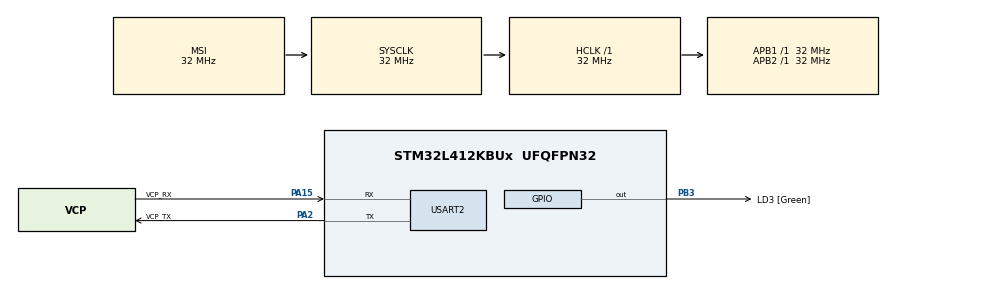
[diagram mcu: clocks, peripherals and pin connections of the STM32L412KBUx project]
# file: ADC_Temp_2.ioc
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ADC1.Channel-2\#ChannelRegularConversion=ADC_CHANNEL_TEMPSENSOR
ADC1.Channel-3\#ChannelRegularConversion=ADC_CHANNEL_VREFINT
ADC1.ClockPrescaler=ADC_CLOCK_ASYNC_DIV4
ADC1.ContinuousConvMode=DISABLE
ADC1.DataAlign=ADC_DATAALIGN_RIGHT
ADC1.ExternalTrigConv=ADC_SOFTWARE_START
ADC1.NbrOfConversion=2
ADC1.NbrOfConversionFlag=1
ADC1.OffsetNumber-2\#ChannelRegularConversion=ADC_OFFSET_NONE
ADC1.OffsetNumber-3\#ChannelRegularConversion=ADC_OFFSET_NONE
ADC1.Rank-2\#ChannelRegularConversion=1
ADC1.Rank-3\#ChannelRegularConversion=2
ADC1.SamplingTime-2\#ChannelRegularConversion=ADC_SAMPLETIME_92CYCLES_5
ADC1.SamplingTime-3\#ChannelRegularConversion=ADC_SAMPLETIME_2CYCLES_5
ADC1.master=1
Dma.ADC1.0.Direction=DMA_PERIPH_TO_MEMORY
Dma.ADC1.0.Instance=DMA1_Channel1
Dma.ADC1.0.MemDataAlignment=DMA_MDATAALIGN_HALFWORD
Dma.ADC1.0.MemInc=DMA_MINC_ENABLE
Dma.ADC1.0.Mode=DMA_NORMAL
Dma.ADC1.0.PeriphDataAlignment=DMA_PDATAALIGN_HALFWORD
Dma.ADC1.0.PeriphInc=DMA_PINC_DISABLE
Dma.ADC1.0.Priority=DMA_PRIORITY_LOW
Dma.Request0=ADC1
Mcu.Family=STM32L4
Mcu.Name=STM32L412KBUx
Mcu.Package=UFQFPN32
NVIC.DMA1_Channel1_IRQn=true\:0\:0\:false\:false\:true\:false\:true\:true
NVIC.PriorityGroup=NVIC_PRIORITYGROUP_4
NVIC.TIM2_IRQn=true\:0\:0\:false\:false\:true\:true\:true\:true
PA0-CK_IN.Mode=HSE-External-Clock-Source-for-LittleOrca
PA0-CK_IN.Signal=RCC_CK_IN
PA13\ (JTMS/SWDIO).GPIO_Label=SWDIO
PA13\ (JTMS/SWDIO).Mode=Serial_Wire
PA13\ (JTMS/SWDIO).Signal=SYS_JTMS-SWDIO
PA14\ (JTCK/SWCLK).GPIO_Label=SWCLK
PA14\ (JTCK/SWCLK).Mode=Serial_Wire
PA14\ (JTCK/SWCLK).Signal=SYS_JTCK-SWCLK
PA15\ (JTDI).GPIO_Label=VCP_RX
PA15\ (JTDI).Mode=Asynchronous
PA15\ (JTDI).Signal=USART2_RX
PA2.GPIO_Label=VCP_TX
PA2.Mode=Asynchronous
PA2.Signal=USART2_TX
PB3\ (JTDO/TRACESWO).GPIO_Label=LD3 [Green]
PB3\ (JTDO/TRACESWO).Signal=GPIO_Output
PC14-OSC32_IN\ (PC14).Mode=LSE-External-Oscillator
PC14-OSC32_IN\ (PC14).Signal=RCC_OSC32_IN
PC15-OSC32_OUT\ (PC15).Mode=LSE-External-Oscillator
PC15-OSC32_OUT\ (PC15).Signal=RCC_OSC32_OUT
ProjectManager.HeapSize=0x200
ProjectManager.StackSize=0x400
ProjectManager.TargetToolchain=STM32CubeIDE
RCC.ADCFreq_Value=32000000
RCC.AHBFreq_Value=32000000
RCC.APB1Freq_Value=32000000
RCC.APB1TimFreq_Value=32000000
RCC.APB2Freq_Value=32000000
RCC.APB2TimFreq_Value=32000000
RCC.CortexFreq_Value=32000000
RCC.FLatency=FLASH_LATENCY_1
RCC.HCLKFreq_Value=32000000
RCC.HSE_VALUE=8000000
RCC.HSI48_VALUE=48000000
RCC.HSICalibrationValue=64
RCC.HSI_VALUE=16000000
RCC.MSIClockRange=RCC_MSIRANGE_10
RCC.MSI_VALUE=32000000
RCC.PLLN=18
RCC.SYSCLKFreq_VALUE=32000000
RCC.USBFreq_Value=32000000
RCC.VCOOutputFreq_Value=576000000
TIM2.Period=10000-1
TIM2.Prescaler=6400-1
TIM2.TIM_MasterOutputTrigger=TIM_TRGO_UPDATE
USART2.VirtualMode-Asynchronous=VM_ASYNC
VP_ADC1_TempSens_Input.Mode=IN-TempSens
VP_ADC1_Vref_Input.Mode=IN-Vrefint
VP_TIM2_VS_ClockSourceINT.Mode=Internal
board=NUCLEO-L412KB

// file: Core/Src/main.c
/* USER CODE BEGIN Header */
/**
  ******************************************************************************
  * @file           : main.c
  * @brief          : Main program body
  ******************************************************************************
  * @attention
  *
  * Copyright (c) 2024 STMicroelectronics.
  * All rights reserved.
  *
  * This software is licensed under terms that can be found in the LICENSE file
  * in the root directory of this software component.
  * If no LICENSE file comes with this software, it is provided AS-IS.
  *
  ******************************************************************************
  */
/* USER CODE END Header */
#include "main.h"
#include "adc.h"
#include "dma.h"
#include "tim.h"
#include "usart.h"
#include "gpio.h"

/* USER CODE BEGIN Includes */
#include "math.h"
#include <stdbool.h>
/* USER CODE END Includes */

/* USER CODE BEGIN PV */

static bool flag_ADCDone = false;
uint16_t ADCValue[2];
float TemperatureValue = 0;
float VrefVoltage = 0;

/* USER CODE END PV */

void SystemClock_Config(void);

/* USER CODE BEGIN 0 */

/* printf IO */
#ifdef __GNUC__
/* With GCC, small printf (option LD Linker->Libraries->Small printf
   set to 'Yes') calls __io_putchar() */
#define PUTCHAR_PROTOTYPE int __io_putchar(int ch)
#else
#define PUTCHAR_PROTOTYPE int fputc(int ch, FILE *f)
#endif /* __GNUC__ */
PUTCHAR_PROTOTYPE
{
   HAL_UART_Transmit(&huart2, (uint8_t *)&ch, 1, 0xFFFF);
   return ch;
}

void ADCInit(void)
{
	HAL_ADCEx_Calibration_Start(&hadc1, ADC_SINGLE_ENDED); /* ADC Calibration */
	HAL_Delay(1);
	HAL_ADC_Start_DMA(&hadc1, (uint32_t *)ADCValue, 2); /* ADC ?��?�� */
}

/**
* @brief ADC ?���?? ?��?��?��?��
*
* @param hadc
*/
void HAL_ADC_ConvCpltCallback(ADC_HandleTypeDef *hadc)
{
	flag_ADCDone = true;
}

void ADCLoop(void)
{
	if(flag_ADCDone)
	{
		// printf("%d %d %d", ADCValue[0], ADCValue[1], ADCValue[2]);
		VrefVoltage = __HAL_ADC_CALC_VREFANALOG_VOLTAGE( ADCValue[1], ADC_RESOLUTION_12B);
		TemperatureValue = __HAL_ADC_CALC_TEMPERATURE(VrefVoltage, ADCValue[0], ADC_RESOLUTION_12B);
		printf("Vref: %f Temperature: %f\r\n", VrefVoltage, TemperatureValue);

		flag_ADCDone = false;
		HAL_ADC_Start_DMA(&hadc1, (uint32_t *)ADCValue, 2); /* ADC ?��?�� */
	}
}

/* USER CODE END 0 */

int main(void)
{

  /* MCU Configuration--------------------------------------------------------*/

  /* Reset of all peripherals, Initializes the Flash interface and the Systick. */
  HAL_Init();

  /* Configure the system clock */
  SystemClock_Config();

  /* Initialize all configured peripherals */
  MX_GPIO_Init();
  MX_DMA_Init();
  MX_USART2_UART_Init();
  MX_ADC1_Init();
  MX_TIM2_Init();
  /* USER CODE BEGIN 2 */
  // HAL_ADCEx_Calibration_Start(&hadc1, ADC_SINGLE_ENDED);
  //HAL_TIM_Base_Start(&htim2);
  // HAL_ADC_Start_IT(&hadc1);
  ADCInit();
  /* USER CODE END 2 */

  /* Infinite loop */
  while (1)
  {

    /* USER CODE BEGIN 3 */

 ADCLoop();
  }
  /* USER CODE END 3 */
}

void SystemClock_Config(void)
{
  RCC_OscInitTypeDef RCC_OscInitStruct = {0};
  RCC_ClkInitTypeDef RCC_ClkInitStruct = {0};

  /** Configure the main internal regulator output voltage
  */
  if (HAL_PWREx_ControlVoltageScaling(PWR_REGULATOR_VOLTAGE_SCALE1) != HAL_OK)
  {
    Error_Handler();
  }

  /** Configure LSE Drive Capability
  */
  HAL_PWR_EnableBkUpAccess();
  __HAL_RCC_LSEDRIVE_CONFIG(RCC_LSEDRIVE_LOW);

  /** Initializes the RCC Oscillators according to the specified parameters
  * in the RCC_OscInitTypeDef structure.
  */
  RCC_OscInitStruct.OscillatorType = RCC_OSCILLATORTYPE_LSE|RCC_OSCILLATORTYPE_MSI;
  RCC_OscInitStruct.LSEState = RCC_LSE_ON;
  RCC_OscInitStruct.MSIState = RCC_MSI_ON;
  RCC_OscInitStruct.MSICalibrationValue = 0;
  RCC_OscInitStruct.MSIClockRange = RCC_MSIRANGE_10;
  RCC_OscInitStruct.PLL.PLLState = RCC_PLL_NONE;
  if (HAL_RCC_OscConfig(&RCC_OscInitStruct) != HAL_OK)
  {
    Error_Handler();
  }

  /** Initializes the CPU, AHB and APB buses clocks
  */
  RCC_ClkInitStruct.ClockType = RCC_CLOCKTYPE_HCLK|RCC_CLOCKTYPE_SYSCLK
                              |RCC_CLOCKTYPE_PCLK1|RCC_CLOCKTYPE_PCLK2;
  RCC_ClkInitStruct.SYSCLKSource = RCC_SYSCLKSOURCE_MSI;
  RCC_ClkInitStruct.AHBCLKDivider = RCC_SYSCLK_DIV1;
  RCC_ClkInitStruct.APB1CLKDivider = RCC_HCLK_DIV1;
  RCC_ClkInitStruct.APB2CLKDivider = RCC_HCLK_DIV1;

  if (HAL_RCC_ClockConfig(&RCC_ClkInitStruct, FLASH_LATENCY_1) != HAL_OK)
  {
    Error_Handler();
  }

  /** Enable MSI Auto calibration
  */
  HAL_RCCEx_EnableMSIPLLMode();
}

void Error_Handler(void)
{
  __disable_irq();
  while (1)
  {
  }
}
